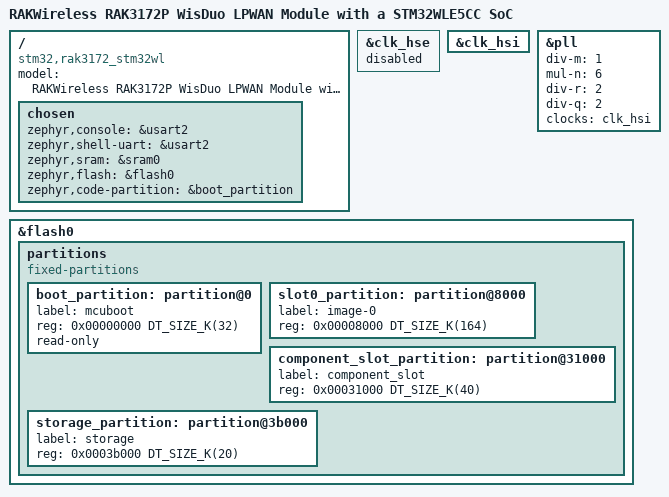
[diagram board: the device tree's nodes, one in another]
/ {
	model = "RAKWireless RAK3172P WisDuo LPWAN Module with a STM32WLE5CC SoC";
	compatible = "stm32,rak3172_stm32wl";

	chosen {
		zephyr,console = &usart2;
		zephyr,shell-uart = &usart2;
		zephyr,sram = &sram0;
		zephyr,flash = &flash0;
		zephyr,code-partition = &boot_partition;
	};
};

&clk_hse {
	status = "disabled";
};

&clk_hsi {
	status = "okay";
};

&pll {
	div-m = <1>;
	mul-n = <6>;
	div-r = <2>;
	div-q = <2>;
	clocks = <&clk_hsi>;
	status = "okay";
};

&flash0 {
	partitions {
		compatible = "fixed-partitions";
		#address-cells = <1>;
		#size-cells = <1>;
	/delete-node/ partition@0;
	/delete-node/ partition@8000;
	/delete-node/ partition@23000;
	/delete-node/ partition@34000;
	/delete-node/ partition@3e000;

		boot_partition: partition@0 {
			label = "mcuboot";
			reg = <0x00000000 DT_SIZE_K(32)>;
			read-only;
		};

	slot0_partition: partition@8000 {
		label = "image-0";
		reg = <0x00008000 DT_SIZE_K(164)>;
	};

	component_slot_partition: partition@31000 {
		label = "component_slot";
		reg = <0x00031000 DT_SIZE_K(40)>;
	};

	storage_partition: partition@3b000 {
		label = "storage";
		reg = <0x0003b000 DT_SIZE_K(20)>;
	};
	};
};
